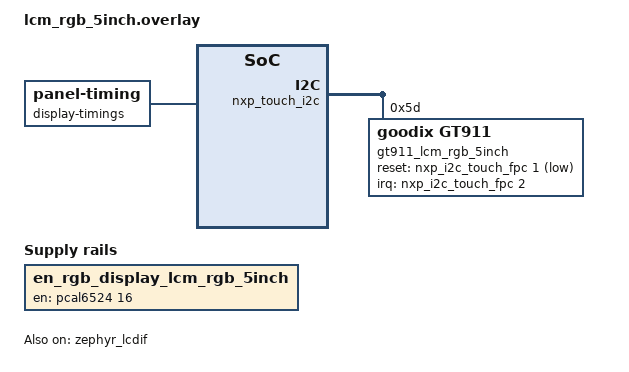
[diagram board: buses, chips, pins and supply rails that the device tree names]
/*
 * Copyright 2026 NXP
 * SPDX-License-Identifier: Apache-2.0
 */

#include <zephyr/dt-bindings/display/panel.h>
#include <zephyr/dt-bindings/gpio/gpio.h>

/ {
	chosen {
		zephyr,display = &zephyr_lcdif;
		zephyr,touch = &gt911_lcm_rgb_5inch;
	};

	en_rgb_display_lcm_rgb_5inch: enable-rgb-display-lcm-rgb-5inch {
		compatible = "regulator-fixed";
		regulator-name = "en_rgb_display";
		enable-gpios = <&pcal6524 16 GPIO_ACTIVE_HIGH>;
		regulator-boot-on;
	};
};

&nxp_touch_i2c {
	status = "okay";

	gt911_lcm_rgb_5inch: gt911-lcm_rgb_5inch@5d {
		compatible = "goodix,gt911";
		reg = <0x5d>;
		reset-gpios = <&nxp_i2c_touch_fpc 1 GPIO_ACTIVE_LOW>; /**/
		irq-gpios = <&nxp_i2c_touch_fpc 2 GPIO_ACTIVE_HIGH>;
	};
};

&zephyr_lcdif {
	status = "okay";

	width = <800>;
	height = <480>;
	pixel-format = <PANEL_PIXEL_FORMAT_RGB_888>;
	data-bus-width = "RGB888";

	display-timings {
		compatible = "zephyr,panel-timing";
		hsync-len = <4>;
		hfront-porch = <8>;
		hback-porch = <8>;
		vsync-len = <4>;
		vfront-porch = <8>;
		vback-porch = <8>;
		de-active = <1>;
		pixelclk-active = <1>;
		hsync-active = <0>;
		vsync-active = <0>;
		/* (800+4+8+8) * (480+4+8+8) * 50 Hz (DEMO_FRAME_RATE) */
		clock-frequency = <20500000>;
	};
};
